AUTOSAR XML (schema 4-3-0)
package /ComponentTypes
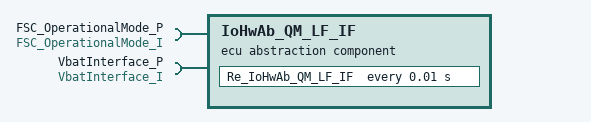
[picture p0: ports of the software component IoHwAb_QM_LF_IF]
  ecu abstraction sw component type IoHwAb_QM_LF_IF
    require port FSC_OperationalMode_P: required-com-specs=[FSC_OperationalMode, VbatInterface_P], required-interface=FSC_OperationalMode_I
    require port VbatInterface_P: required-interface=VbatInterface_I
      required-com-specs:
        DobhsCtrlInterface_P_4
        DobhsCtrlInterface_P_5
        DobhsCtrlInterface_P_3
        DobhsCtrlInterface_P_2
        DobhsCtrlInterface_P_1
        FSC_OperationalMode
        VbatInterface_P
    behavior IoHwAb_QM_LF_IF_InternalBehavior
      timing event TMT_Re_IoHwAb_QM_LF_IF: start-on-event=Re_IoHwAb_QM_LF_IF, period=0.01
      runnable Re_IoHwAb_QM_LF_IF
  swc implementation IoHwAb_QM_LF_IF_Implementation: behavior=IoHwAb_QM_LF_IF_InternalBehavior
